# STM32WB10CCU6 register map
File version: 1.0
Registers are 32-bit, access not given, reset 0x0 unless marked. A register's access mark holds for its fields unless they carry their own. Offsets are from the block's base; [hi:lo] are bit positions; {n}, {i} and the like mark numbered series; 'fields as' and 'values as' point back to an identical list.

## DMA1
Base 0x40020000
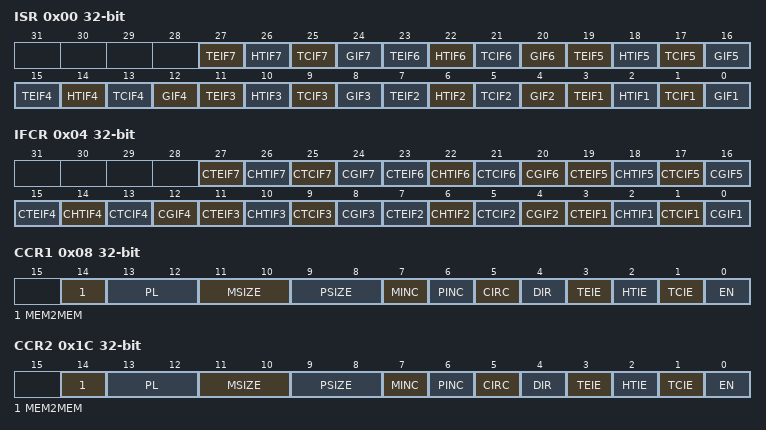
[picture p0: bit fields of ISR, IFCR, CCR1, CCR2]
0x00 ISR
  [4n-1] TEIF{n} (n=1..7), [4n-2] HTIF{n} (n=1..7), [4n-3] TCIF{n} (n=1..7), [4n-4] GIF{n} (n=1..7)
0x04 IFCR
  [4n-1] CTEIF{n} (n=1..7), [4n-2] CHTIF{n} (n=1..7), [4n-3] CTCIF{n} (n=1..7), [4n-4] CGIF{n} (n=1..7)
0x08 CCR1
  [14] MEM2MEM, [13:12] PL, [11:10] MSIZE, [9:8] PSIZE, [7] MINC, [6] PINC, [5] CIRC, [4] DIR, [3] TEIE, [2] HTIE, [1] TCIE, [0] EN
0x0C CNDTR1
  [15:0] NDTR
0x10 CPAR1
  [31:0] PA
{0x0+0x14*i} CMAR{i} (i=1..7)
  [31:0] MA
0x1C CCR2
  fields as CCR1
0x20 CNDTR2
  [15:0] NDTR
0x24 CPAR2
  [31:0] PA
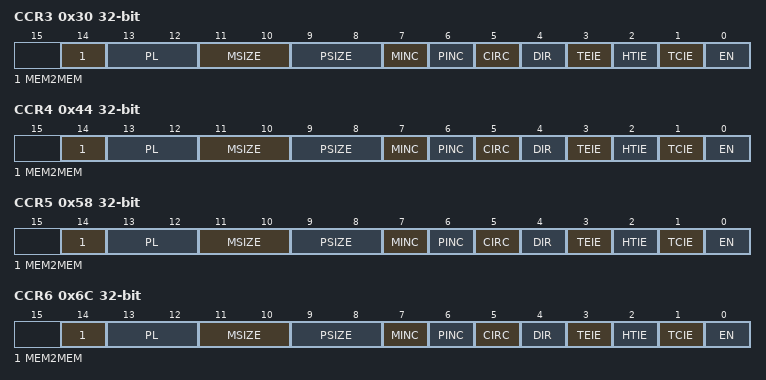
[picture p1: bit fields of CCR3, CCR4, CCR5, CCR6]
0x30 CCR3
  fields as CCR1
0x34 CNDTR3
  [15:0] NDTR
0x38 CPAR3
  [31:0] PA
0x44 CCR4
  fields as CCR1
0x48 CNDTR4
  [15:0] NDTR
0x4C CPAR4
  [31:0] PA
0x58 CCR5
  fields as CCR1
0x5C CNDTR5
  [15:0] NDTR
0x60 CPAR5
  [31:0] PA
0x6C CCR6
  fields as CCR1
0x70 CNDTR6
  [15:0] NDTR
0x74 CPAR6
  [31:0] PA
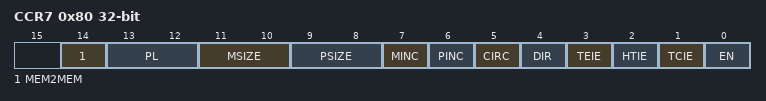
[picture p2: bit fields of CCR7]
0x80 CCR7
  fields as CCR1
0x84 CNDTR7
  [15:0] NDTR
0x88 CPAR7
  [31:0] PA

## DMAMUX
Base 0x40020800
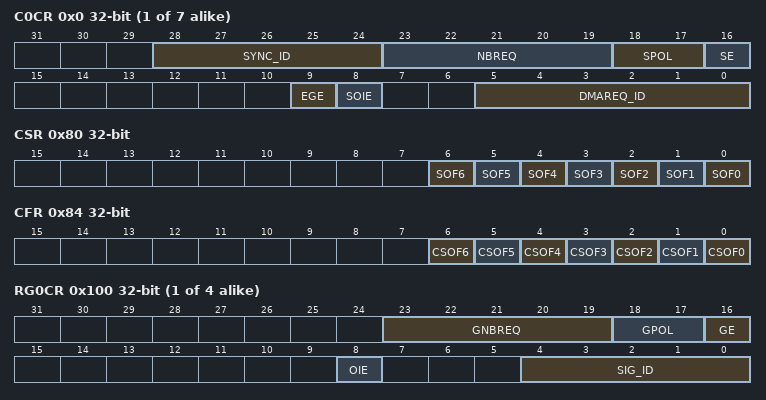
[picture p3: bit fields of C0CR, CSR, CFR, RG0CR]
{0x0+4i} C{i}CR (i=0..6)
  [28:24] SYNC_ID, [23:19] NBREQ, [18:17] SPOL, [16] SE, [9] EGE, [8] SOIE, [5:0] DMAREQ_ID
0x80 CSR
  [n] SOF{n} (n=0..6)
0x84 CFR
  [n] CSOF{n} (n=0..6)
{0x100+4i} RG{i}CR (i=0..3)
  [23:19] GNBREQ, [18:17] GPOL, [16] GE, [8] OIE, [4:0] SIG_ID
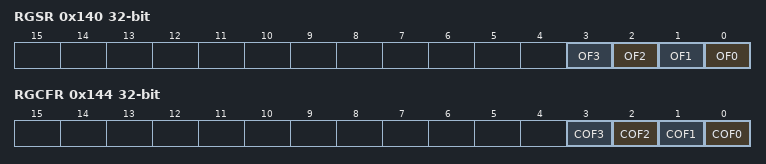
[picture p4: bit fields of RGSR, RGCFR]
0x140 RGSR
  [n] OF{n} (n=0..3)
0x144 RGCFR
  [n] COF{n} (n=0..3)

## CRC
Base 0x40023000
0x00 DR
0x04 IDR
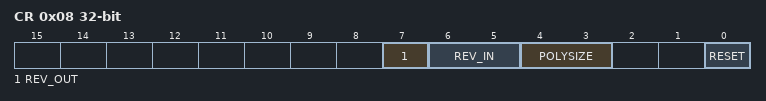
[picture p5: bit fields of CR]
0x08 CR
  [7] REV_OUT, [6:5] REV_IN, [4:3] POLYSIZE, [0] RESET
0x10 INIT
  [31:0] CRC_INIT
0x14 POL

## TSC
Base 0x40024000
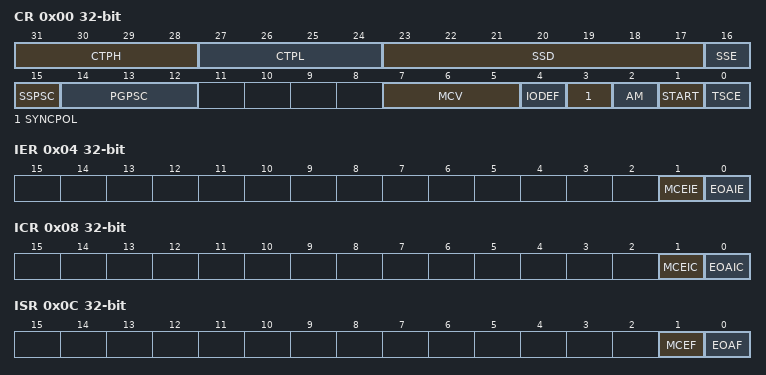
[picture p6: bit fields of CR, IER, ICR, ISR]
0x00 CR
  [31:28] CTPH, [27:24] CTPL, [23:17] SSD, [16] SSE, [15] SSPSC, [14:12] PGPSC, [7:5] MCV, [4] IODEF, [3] SYNCPOL, [2] AM, [1] START, [0] TSCE
0x04 IER
  [1] MCEIE, [0] EOAIE
0x08 ICR
  [1] MCEIC, [0] EOAIC
0x0C ISR
  [1] MCEF, [0] EOAF
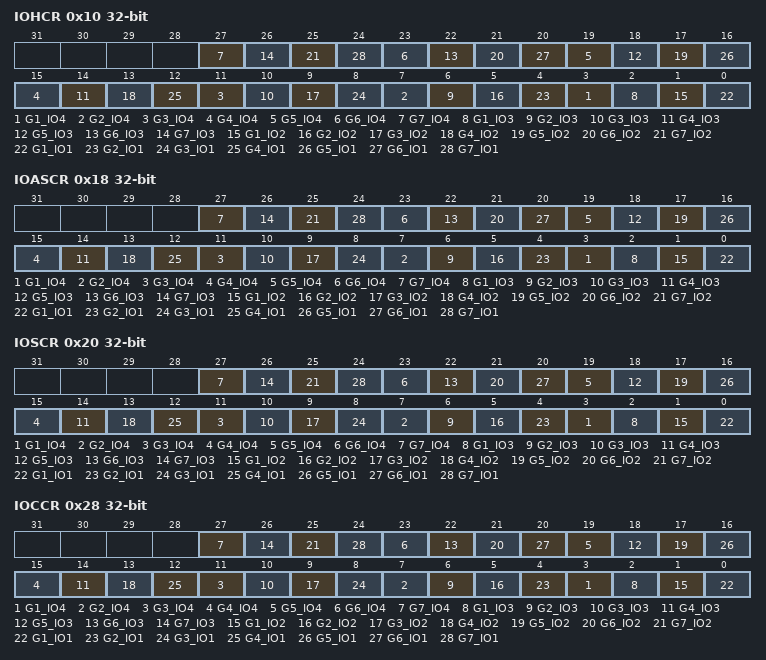
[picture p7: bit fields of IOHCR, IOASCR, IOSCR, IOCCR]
0x10 IOHCR
  [4n-1] G{n}_IO4 (n=1..7), [4n-2] G{n}_IO3 (n=1..7), [4n-3] G{n}_IO2 (n=1..7), [4n-4] G{n}_IO1 (n=1..7)
0x18 IOASCR
  fields as IOHCR
0x20 IOSCR
  fields as IOHCR
0x28 IOCCR
  fields as IOHCR
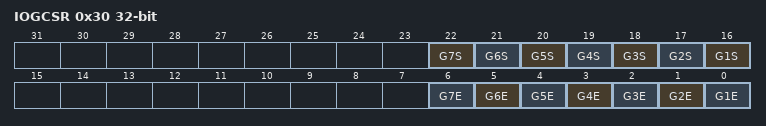
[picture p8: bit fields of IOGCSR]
0x30 IOGCSR
  [n+15] G{n}S (n=1..7), [n-1] G{n}E (n=1..7)
{0x30+4i} IOG{i}CR (i=1..7)
  [13:0] CNT

## GPIOA
Base 0x48000000
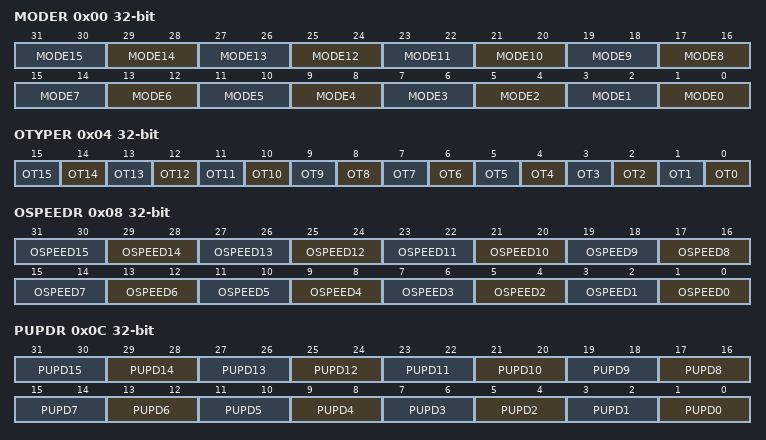
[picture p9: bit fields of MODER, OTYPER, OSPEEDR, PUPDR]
0x00 MODER
  [2n+1:2n] MODE{n} (n=0..15)
0x04 OTYPER
  [n] OT{n} (n=0..15)
0x08 OSPEEDR
  [2n+1:2n] OSPEED{n} (n=0..15)
0x0C PUPDR
  [2n+1:2n] PUPD{n} (n=0..15)
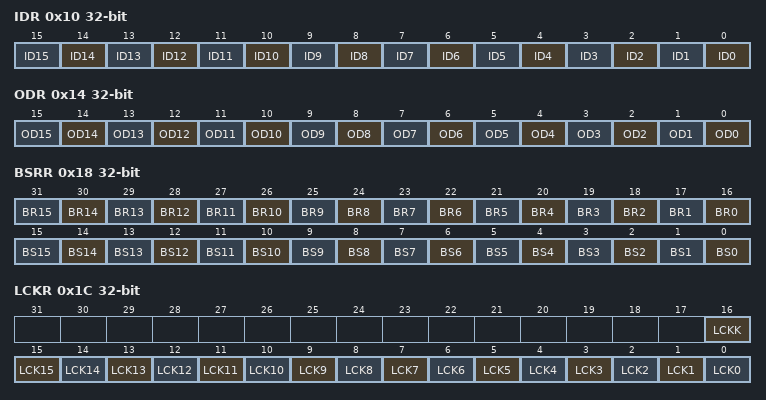
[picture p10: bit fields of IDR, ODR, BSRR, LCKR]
0x10 IDR
  [n] ID{n} (n=0..15)
0x14 ODR
  [n] OD{n} (n=0..15)
0x18 BSRR
  [n+16] BR{n} (n=0..15), [n] BS{n} (n=0..15)
0x1C LCKR
  [16] LCKK, [n] LCK{n} (n=0..15)
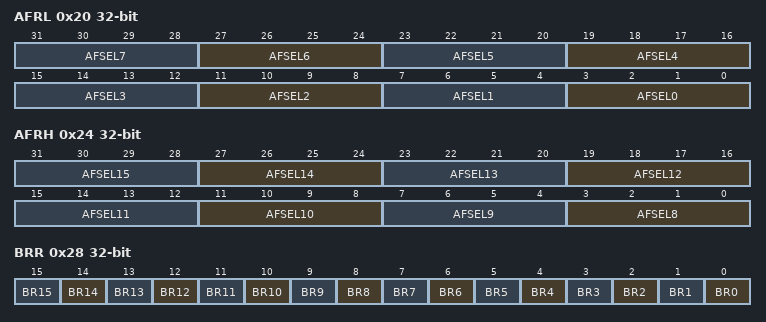
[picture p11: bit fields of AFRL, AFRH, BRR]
0x20 AFRL
  [4n+3:4n] AFSEL{n} (n=0..7)
0x24 AFRH
  [4n-29:4n-32] AFSEL{n} (n=8..15)
0x28 BRR
  [n] BR{n} (n=0..15)

## GPIOB
Base 0x48000400
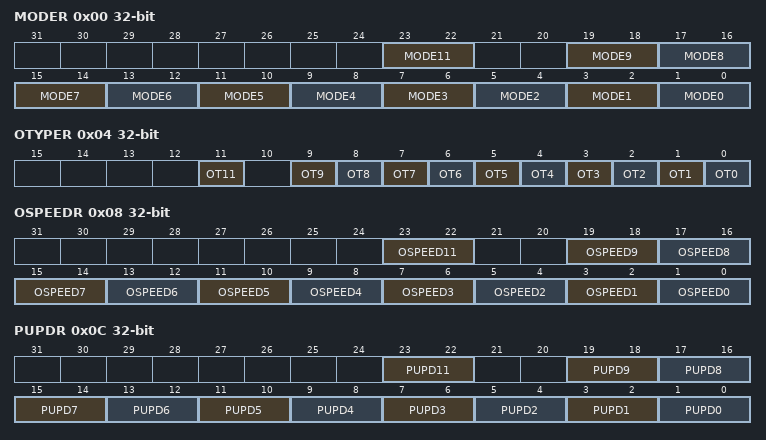
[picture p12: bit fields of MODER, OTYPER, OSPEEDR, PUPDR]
0x00 MODER
  [23:22] MODE11, [2n+1:2n] MODE{n} (n=0..9)
0x04 OTYPER
  [11] OT11, [n] OT{n} (n=0..9)
0x08 OSPEEDR
  [23:22] OSPEED11, [2n+1:2n] OSPEED{n} (n=0..9)
0x0C PUPDR
  [23:22] PUPD11, [2n+1:2n] PUPD{n} (n=0..9)
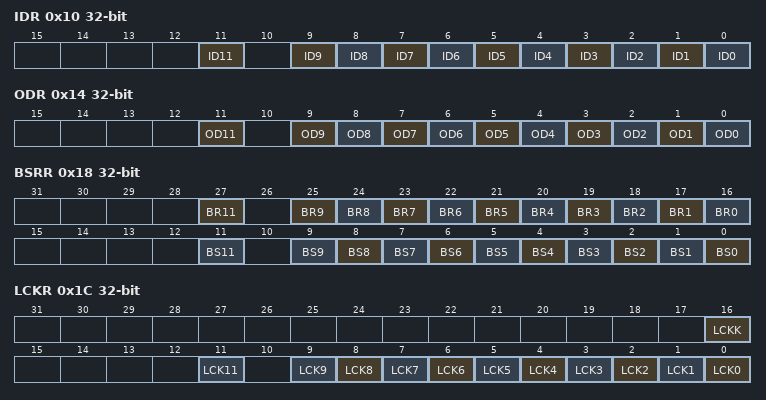
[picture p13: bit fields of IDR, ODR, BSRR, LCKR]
0x10 IDR
  [11] ID11, [n] ID{n} (n=0..9)
0x14 ODR
  [11] OD11, [n] OD{n} (n=0..9)
0x18 BSRR
  [27] BR11, [n+16] BR{n} (n=0..9), [11] BS11, [n] BS{n} (n=0..9)
0x1C LCKR
  [16] LCKK, [11] LCK11, [n] LCK{n} (n=0..9)
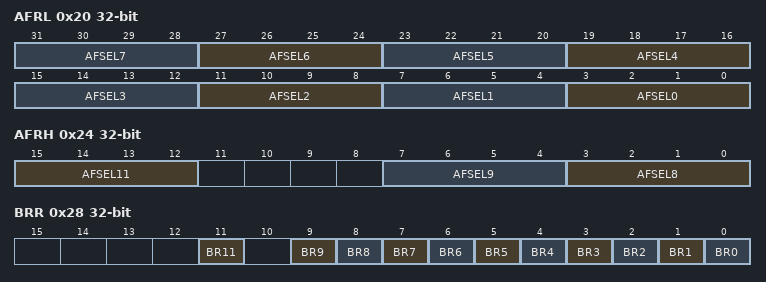
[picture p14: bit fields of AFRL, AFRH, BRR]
0x20 AFRL
  [4n+3:4n] AFSEL{n} (n=0..7)
0x24 AFRH
  [15:12] AFSEL11, [7:4] AFSEL9, [3:0] AFSEL8
0x28 BRR
  [11] BR11, [n] BR{n} (n=0..9)

## GPIOC
Base 0x48000800
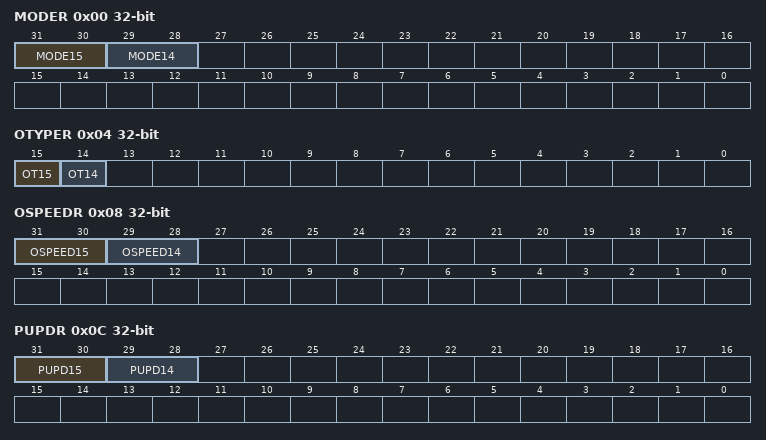
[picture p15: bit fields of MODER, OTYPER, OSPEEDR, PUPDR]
0x00 MODER
  [31:30] MODE15, [29:28] MODE14
0x04 OTYPER
  [15] OT15, [14] OT14
0x08 OSPEEDR
  [31:30] OSPEED15, [29:28] OSPEED14
0x0C PUPDR
  [31:30] PUPD15, [29:28] PUPD14
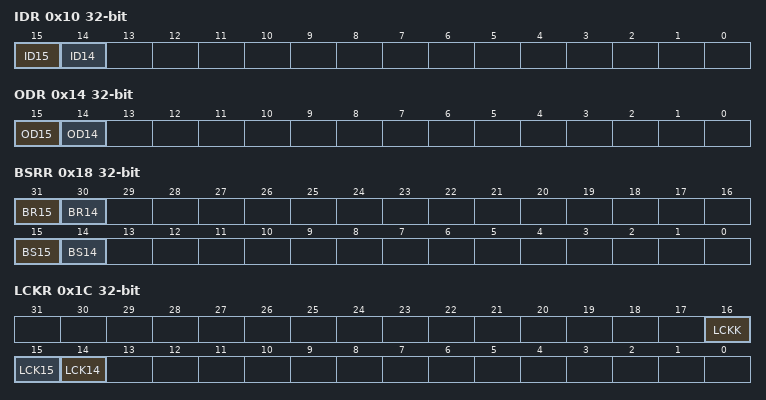
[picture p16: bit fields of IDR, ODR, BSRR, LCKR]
0x10 IDR
  [15] ID15, [14] ID14
0x14 ODR
  [15] OD15, [14] OD14
0x18 BSRR
  [31] BR15, [30] BR14, [15] BS15, [14] BS14
0x1C LCKR
  [16] LCKK, [15] LCK15, [14] LCK14
0x20 AFRL
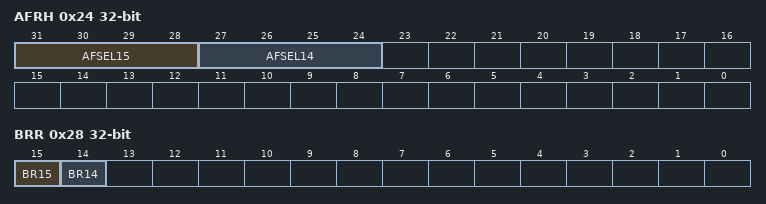
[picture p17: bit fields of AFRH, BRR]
0x24 AFRH
  [31:28] AFSEL15, [27:24] AFSEL14
0x28 BRR
  [15] BR15, [14] BR14

## GPIOE
Base 0x48001000
0x00 MODER
  [9:8] MODE4
0x04 OTYPER
  [4] OT4
0x08 OSPEEDR
  [9:8] OSPEED4
0x0C PUPDR
  [9:8] PUPD4
0x10 IDR
  [4] ID4
0x14 ODR
  [4] OD4
0x18 BSRR
  [20] BR4, [4] BS4
0x1C LCKR
  [16] LCKK, [4] LCK4
0x20 AFRL
  [19:16] AFSEL4
0x24 AFRH
0x28 BRR
  [4] BR4
